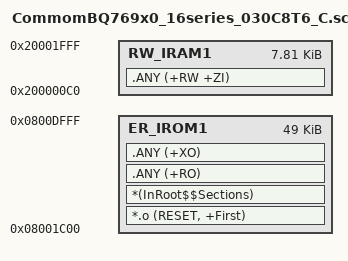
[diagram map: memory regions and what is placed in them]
; *************************************************************
; *** Scatter-Loading Description File generated by uVision ***
; *************************************************************

LR_IROM1 0x08001C00 0x0000C400  {    ; 0x0800E000..0x0800FFFF reserved for flash storage
  ER_IROM1 0x08001C00 0x0000C400  {  ; load address = execution address
   *.o (RESET, +First)
   *(InRoot$$Sections)
   .ANY (+RO)
   .ANY (+XO)
  }
  RW_IRAM1 0x200000C0 0x00001F40  {  ; RW data
   .ANY (+RW +ZI)
  }
}
